NS_ :

BS_:

BO_ 768 VEHICLE_STATE: 8 ADAS
 SG_ SET_ME_XF9 : 7|8@0+ (1,0) [0|255] "" Vector__XXX
 SG_ VEHICLE_SPEED : 15|8@0+ (1,0) [0|255] "kph" Vector__XXX

BO_ 769 VEHICLE_STATE2: 8 ADAS
 SG_ SET_ME_0F18510 : 7|28@0+ (1,0) [0|268435455] "" Vector__XXX
 SG_ SET_ME_25A0000 : 27|28@0+ (1,0) [0|268435455] "" Vector__XXX

BO_ 1024 RADAR_DIAGNOSTIC: 8 RADAR
 SG_ RADAR_STATE : 7|8@0+ (1,0) [0|255] "" NEO

BO_ 1040 XXX_101: 8 RADAR

BO_ 1041 XXX_102: 8 RADAR

BO_ 1042 XXX_103: 8 RADAR

BO_ 1043 XXX_104: 8 RADAR

BO_ 1044 XXX_105: 8 RADAR

BO_ 1045 XXX_106: 8 RADAR

BO_ 1046 XXX_107: 8 RADAR

BO_ 1047 XXX_108: 8 RADAR

BO_ 1056 XXX_109: 8 RADAR

BO_ 1057 XXX_110: 8 RADAR

BO_ 1058 XXX_111: 8 RADAR

BO_ 1059 XXX_112: 8 RADAR

BO_ 1060 XXX_113: 8 RADAR

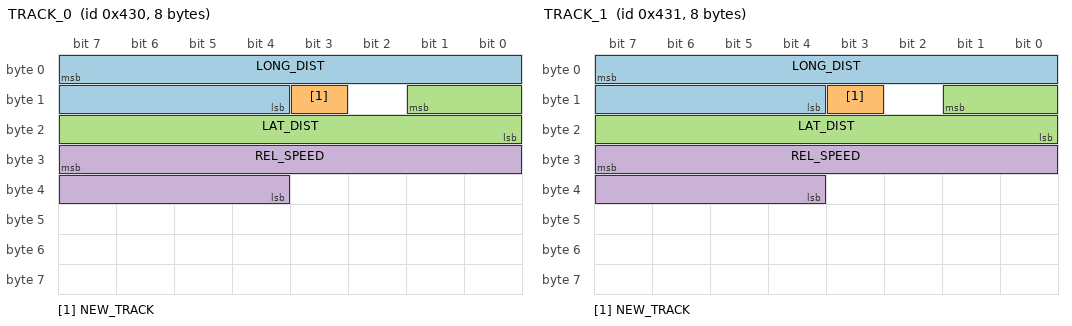
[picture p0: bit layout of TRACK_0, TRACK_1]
BO_ 1072 TRACK_0: 8 RADAR
 SG_ LONG_DIST : 7|12@0+ (0.0625,0) [0|255.5] "m"  NEO
 SG_ NEW_TRACK : 11|1@0+ (1,0) [0|1] ""  NEO
 SG_ LAT_DIST : 9|10@0- (0.0625,0) [0|63.5] "m"  NEO
 SG_ REL_SPEED : 31|12@0- (0.03125,0) [0|127.5] "m/s"  NEO

BO_ 1073 TRACK_1: 8 RADAR
 SG_ LONG_DIST : 7|12@0+ (0.0625,0) [0|255.5] "m"  NEO
 SG_ NEW_TRACK : 11|1@0+ (1,0) [0|1] ""  NEO
 SG_ LAT_DIST : 9|10@0- (0.0625,0) [0|63.5] "m"  NEO
 SG_ REL_SPEED : 31|12@0- (0.03125,0) [0|127.5] "m/s"  NEO

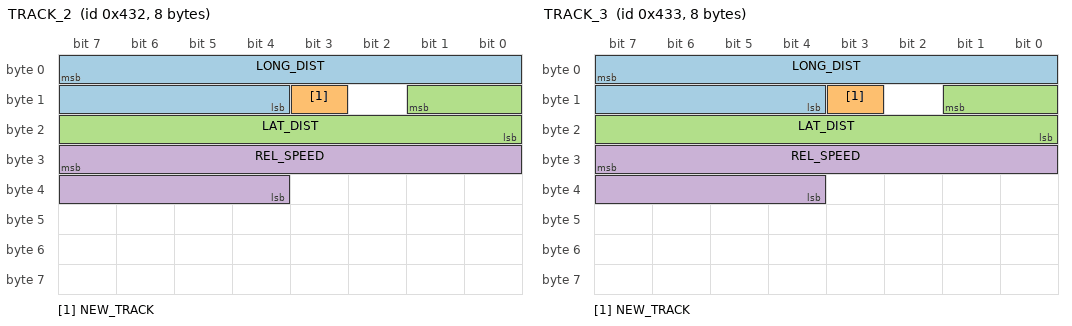
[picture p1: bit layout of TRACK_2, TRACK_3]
BO_ 1074 TRACK_2: 8 RADAR
 SG_ LONG_DIST : 7|12@0+ (0.0625,0) [0|255.5] "m"  NEO
 SG_ NEW_TRACK : 11|1@0+ (1,0) [0|1] ""  NEO
 SG_ LAT_DIST : 9|10@0- (0.0625,0) [0|63.5] "m"  NEO
 SG_ REL_SPEED : 31|12@0- (0.03125,0) [0|127.5] "m/s"  NEO

BO_ 1075 TRACK_3: 8 RADAR
 SG_ LONG_DIST : 7|12@0+ (0.0625,0) [0|255.5] "m"  NEO
 SG_ NEW_TRACK : 11|1@0+ (1,0) [0|1] ""  NEO
 SG_ LAT_DIST : 9|10@0- (0.0625,0) [0|63.5] "m"  NEO
 SG_ REL_SPEED : 31|12@0- (0.03125,0) [0|127.5] "m/s"  NEO

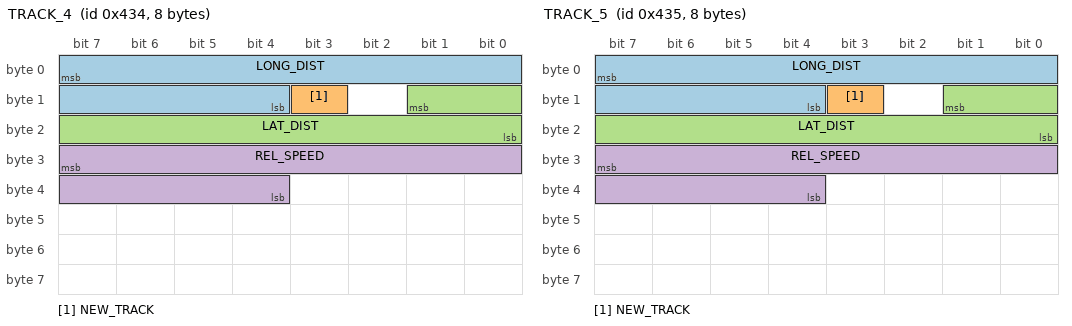
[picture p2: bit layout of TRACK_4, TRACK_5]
BO_ 1076 TRACK_4: 8 RADAR
 SG_ LONG_DIST : 7|12@0+ (0.0625,0) [0|255.5] "m"  NEO
 SG_ NEW_TRACK : 11|1@0+ (1,0) [0|1] ""  NEO
 SG_ LAT_DIST : 9|10@0- (0.0625,0) [0|63.5] "m"  NEO
 SG_ REL_SPEED : 31|12@0- (0.03125,0) [0|127.5] "m/s"  NEO

BO_ 1077 TRACK_5: 8 RADAR
 SG_ LONG_DIST : 7|12@0+ (0.0625,0) [0|255.5] "m"  NEO
 SG_ NEW_TRACK : 11|1@0+ (1,0) [0|1] ""  NEO
 SG_ LAT_DIST : 9|10@0- (0.0625,0) [0|63.5] "m"  NEO
 SG_ REL_SPEED : 31|12@0- (0.03125,0) [0|127.5] "m/s"  NEO

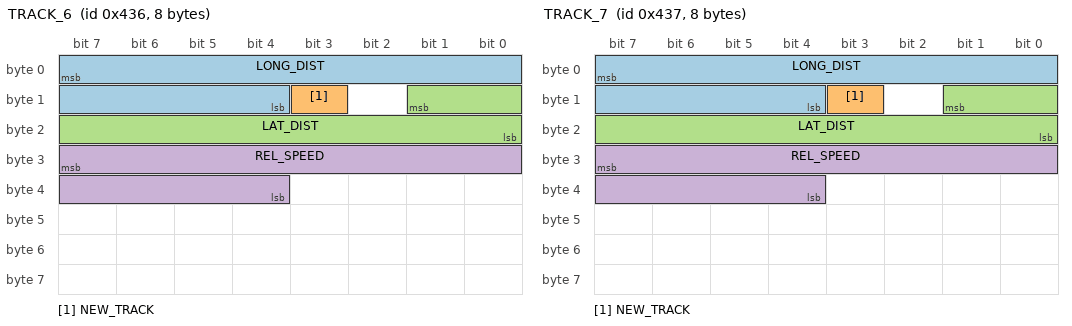
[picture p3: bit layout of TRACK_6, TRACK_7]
BO_ 1078 TRACK_6: 8 RADAR
 SG_ LONG_DIST : 7|12@0+ (0.0625,0) [0|255.5] "m"  NEO
 SG_ NEW_TRACK : 11|1@0+ (1,0) [0|1] ""  NEO
 SG_ LAT_DIST : 9|10@0- (0.0625,0) [0|63.5] "m"  NEO
 SG_ REL_SPEED : 31|12@0- (0.03125,0) [0|127.5] "m/s"  NEO

BO_ 1079 TRACK_7: 8 RADAR
 SG_ LONG_DIST : 7|12@0+ (0.0625,0) [0|255.5] "m"  NEO
 SG_ NEW_TRACK : 11|1@0+ (1,0) [0|1] ""  NEO
 SG_ LAT_DIST : 9|10@0- (0.0625,0) [0|63.5] "m"  NEO
 SG_ REL_SPEED : 31|12@0- (0.03125,0) [0|127.5] "m/s"  NEO

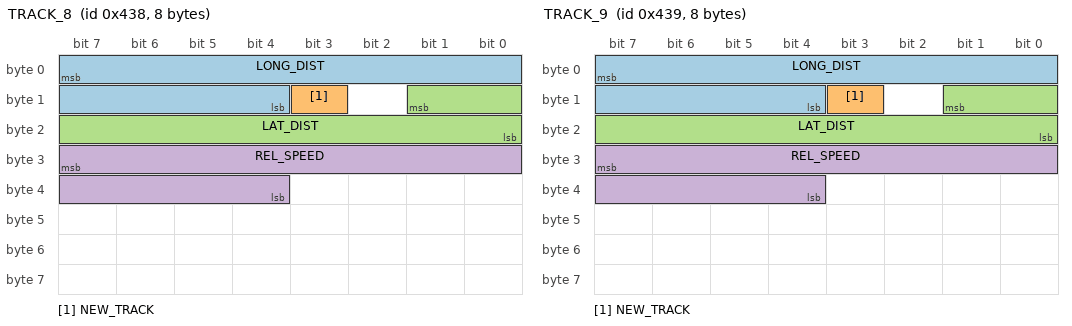
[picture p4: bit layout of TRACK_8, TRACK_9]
BO_ 1080 TRACK_8: 8 RADAR
 SG_ LONG_DIST : 7|12@0+ (0.0625,0) [0|255.5] "m"  NEO
 SG_ NEW_TRACK : 11|1@0+ (1,0) [0|1] ""  NEO
 SG_ LAT_DIST : 9|10@0- (0.0625,0) [0|63.5] "m"  NEO
 SG_ REL_SPEED : 31|12@0- (0.03125,0) [0|127.5] "m/s"  NEO

BO_ 1081 TRACK_9: 8 RADAR
 SG_ LONG_DIST : 7|12@0+ (0.0625,0) [0|255.5] "m"  NEO
 SG_ NEW_TRACK : 11|1@0+ (1,0) [0|1] ""  NEO
 SG_ LAT_DIST : 9|10@0- (0.0625,0) [0|63.5] "m"  NEO
 SG_ REL_SPEED : 31|12@0- (0.03125,0) [0|127.5] "m/s"  NEO

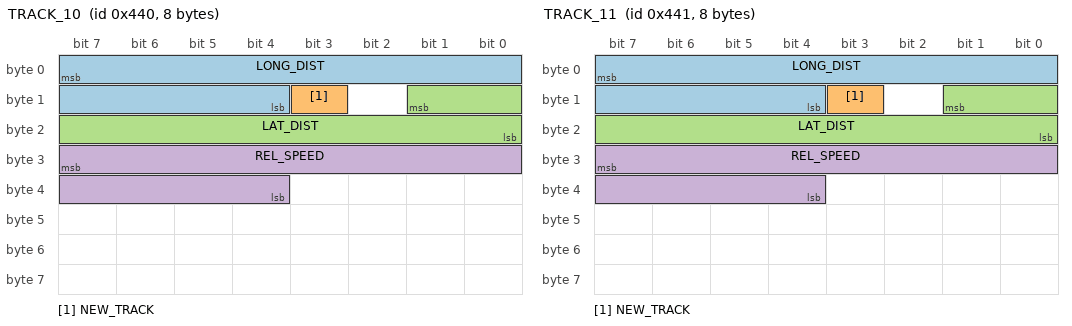
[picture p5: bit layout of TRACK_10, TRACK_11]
BO_ 1088 TRACK_10: 8 RADAR
 SG_ LONG_DIST : 7|12@0+ (0.0625,0) [0|255.5] "m"  NEO
 SG_ NEW_TRACK : 11|1@0+ (1,0) [0|1] ""  NEO
 SG_ LAT_DIST : 9|10@0- (0.0625,0) [0|63.5] "m"  NEO
 SG_ REL_SPEED : 31|12@0- (0.03125,0) [0|127.5] "m/s"  NEO

BO_ 1089 TRACK_11: 8 RADAR
 SG_ LONG_DIST : 7|12@0+ (0.0625,0) [0|255.5] "m"  NEO
 SG_ NEW_TRACK : 11|1@0+ (1,0) [0|1] ""  NEO
 SG_ LAT_DIST : 9|10@0- (0.0625,0) [0|63.5] "m"  NEO
 SG_ REL_SPEED : 31|12@0- (0.03125,0) [0|127.5] "m/s"  NEO

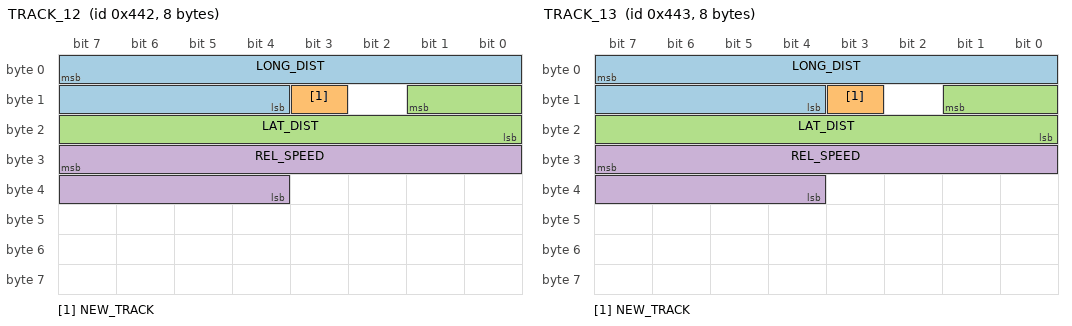
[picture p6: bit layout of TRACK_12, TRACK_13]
BO_ 1090 TRACK_12: 8 RADAR
 SG_ LONG_DIST : 7|12@0+ (0.0625,0) [0|255.5] "m"  NEO
 SG_ NEW_TRACK : 11|1@0+ (1,0) [0|1] ""  NEO
 SG_ LAT_DIST : 9|10@0- (0.0625,0) [0|63.5] "m"  NEO
 SG_ REL_SPEED : 31|12@0- (0.03125,0) [0|127.5] "m/s"  NEO

BO_ 1091 TRACK_13: 8 RADAR
 SG_ LONG_DIST : 7|12@0+ (0.0625,0) [0|255.5] "m"  NEO
 SG_ NEW_TRACK : 11|1@0+ (1,0) [0|1] ""  NEO
 SG_ LAT_DIST : 9|10@0- (0.0625,0) [0|63.5] "m"  NEO
 SG_ REL_SPEED : 31|12@0- (0.03125,0) [0|127.5] "m/s"  NEO

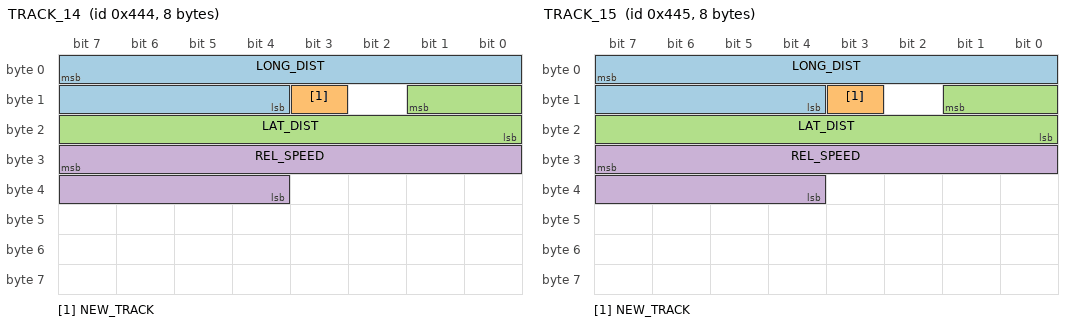
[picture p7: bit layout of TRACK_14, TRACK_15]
BO_ 1092 TRACK_14: 8 RADAR
 SG_ LONG_DIST : 7|12@0+ (0.0625,0) [0|255.5] "m"  NEO
 SG_ NEW_TRACK : 11|1@0+ (1,0) [0|1] ""  NEO
 SG_ LAT_DIST : 9|10@0- (0.0625,0) [0|63.5] "m"  NEO
 SG_ REL_SPEED : 31|12@0- (0.03125,0) [0|127.5] "m/s"  NEO

BO_ 1093 TRACK_15: 8 RADAR
 SG_ LONG_DIST : 7|12@0+ (0.0625,0) [0|255.5] "m"  NEO
 SG_ NEW_TRACK : 11|1@0+ (1,0) [0|1] ""  NEO
 SG_ LAT_DIST : 9|10@0- (0.0625,0) [0|63.5] "m"  NEO
 SG_ REL_SPEED : 31|12@0- (0.03125,0) [0|127.5] "m/s"  NEO

BO_ 1279 XXX_114: 8 RADAR

BO_ 1280 XXX_115: 8 RADAR

BO_ 1296 XXX_116: 8 RADAR

BO_ 1297 XXX_117: 8 RADAR

BO_TX_BU_ 768 : NEO,ADAS;
BO_TX_BU_ 769 : NEO,ADAS;

BU_: XXX

CM_ "AUTOGENERATED FILE, DO NOT EDIT";

CM_ "Imported file _honda_common.dbc starts here";
CM_ SG_ 304 "Seems to be platform-agnostic";
CM_ SG_ 316 "Should exist on Nidec";
CM_ SG_ 420 BRAKE_HOLD_RELATED "On when Brake Hold engaged";
CM_ SG_ 490 LONG_ACCEL "wheel speed derivative, noisy and zero snapping";
CM_ SG_ 773 PASS_AIRBAG_ON "Might just be indicator light";
CM_ SG_ 773 PASS_AIRBAG_OFF "Might just be indicator light";
CM_ SG_ 780 CRUISE_SPEED "255 = no speed";
CM_ SG_ 780 PCM_SPEED "Used by Nidec";
CM_ SG_ 780 PCM_GAS "Used by Nidec";
CM_ SG_ 804 CRUISE_SPEED_PCM "255 = no speed";

CM_ "Imported file _bosch_2018.dbc starts here";
CM_ SG_ 450 EPB_STATE "3: On, 2: Disengaging, 1: Engaging, 0: Off";
CM_ SG_ 576 LINE_DISTANCE_VISIBLE "Length of line visible, undecoded";
CM_ SG_ 577 LINE_FAR_EDGE_POSITION "Appears to be a measure of line thickness, indicates location of the portion of the line furthest from the car, undecoded";
CM_ SG_ 577 LINE_PARAMETER "Unclear if this is low quality line curvature rate or if this is something else, but it is correlated with line curvature, undecoded";
CM_ SG_ 577 LINE_DASHED "1 = line is dashed";
CM_ SG_ 577 LINE_SOLID "1 = line is solid";

CM_ "Imported file _bosch_adas_2018.dbc starts here";
CM_ SG_ 479 CONTROL_ON "Set to 5 when car is being controlled";
CM_ SG_ 479 AEB_STATUS "set for the duration of AEB event";
CM_ SG_ 479 AEB_BRAKING "set when braking is commanded during AEB event";
CM_ SG_ 479 AEB_PREPARE "set 1s before AEB";
CM_ SG_ 829 BEEP "beeps are pleasant, chimes are for warnngs etc...";

CM_ "Imported file _steering_sensors_a.dbc starts here";
CM_ "honda_civic_hatchback_ex_2017_can.dbc starts here";
